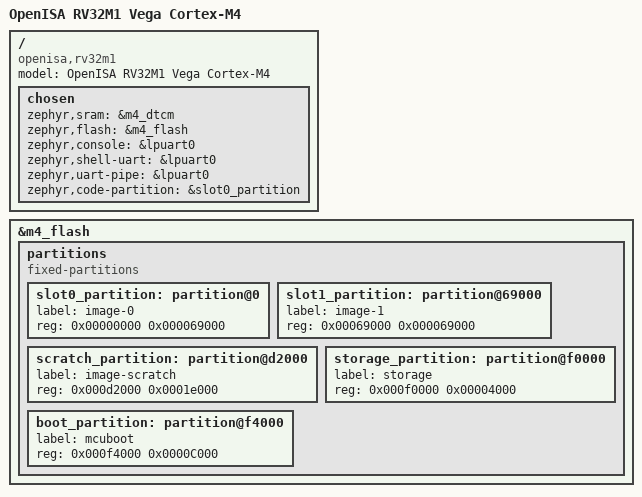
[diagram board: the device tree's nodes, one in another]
/*
 * Copyright (c) 2018 Foundries.io Ltd
 * Copyright (c) 2020 Karsten Koenig
 * SPDX-License-Identifier: Apache-2.0
 */

/dts-v1/;

#include "rv32m1/rv32m1_m4.dtsi"
#include "rv32m1_vega_cortex.dtsi"

/ {
	model = "OpenISA RV32M1 Vega Cortex-M4";
	compatible = "openisa,rv32m1";

	chosen {
		zephyr,sram = &m4_dtcm;
		zephyr,flash = &m4_flash;
		zephyr,console = &lpuart0;
		zephyr,shell-uart = &lpuart0;
		zephyr,uart-pipe = &lpuart0;
		zephyr,code-partition = &slot0_partition;
	};
};

&m4_flash {
	partitions {
		compatible = "fixed-partitions";
		#address-cells = <1>;
		#size-cells = <1>;

		slot0_partition: partition@0 {
			label = "image-0";
			reg = <0x00000000 0x000069000>;
		};
		slot1_partition: partition@69000 {
			label = "image-1";
			reg = <0x00069000 0x000069000>;
		};
		scratch_partition: partition@d2000 {
			label = "image-scratch";
			reg = <0x000d2000 0x0001e000>;
		};
		storage_partition: partition@f0000 {
			label = "storage";
			reg = <0x000f0000 0x00004000>;
		};
		boot_partition: partition@f4000 {
			label = "mcuboot";
			reg = <0x000f4000 0x0000C000>;
		};
	};
};
